AUTOSAR XML (schema 4-3-0)
package /ComponentTypes
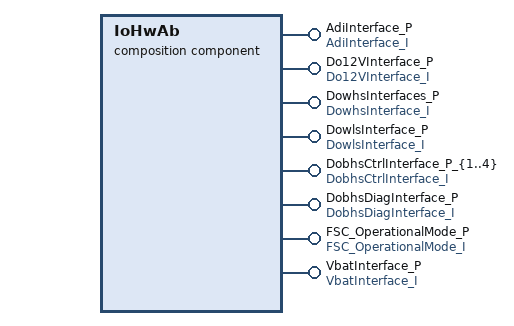
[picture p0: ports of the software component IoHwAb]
  composition sw component type IoHwAb
    11 x provide port:
      AdiInterface_P: provided-interface=AdiInterface_I
      Do12VInterface_P: provided-interface=Do12VInterface_I
      DowhsInterfaces_P: provided-interface=DowhsInterface_I
      DowlsInterface_P: provided-interface=DowlsInterface_I
      DobhsCtrlInterface_P_{1..4}: provided-interface=DobhsCtrlInterface_I
      DobhsDiagInterface_P: server-com-spec{operation=IoHwAbOperation, queue-length=1}, provided-interface=DobhsDiagInterface_I
      FSC_OperationalMode_P: provided-com-specs=[{operation=FSC_OperationalMode, queue-length=1}, {operation=VbatInterface_P, queue-length=1}], provided-interface=FSC_OperationalMode_I
      VbatInterface_P: provided-interface=VbatInterface_I
        provided-com-specs:
          operation=DobhsCtrlInterface_P_4, queue-length=1
          operation=DobhsCtrlInterface_P_5, queue-length=1
          operation=DobhsCtrlInterface_P_3, queue-length=1
          operation=DobhsCtrlInterface_P_2, queue-length=1
          operation=DobhsCtrlInterface_P_1, queue-length=1
          operation=FSC_OperationalMode, queue-length=1
          operation=VbatInterface_P, queue-length=1
    component IoHwAb_ASIL: type=IoHwAb_ASIL
    component IoHwAb_QM: type=IoHwAb_QM
    delegate IoHwAb_ASIL.FSC_OperationalMode <-> outer port FSC_OperationalMode_P
    delegate IoHwAb_ASIL.VbatInterface_P <-> outer port VbatInterface_P
    delegate IoHwAb_QM.AdiInterface_P <-> outer port AdiInterface_P
    delegate IoHwAb_ASIL.DobhsCtrlInterface_P_{1..4} <-> outer port DobhsCtrlInterface_P_{1..4}
    delegate IoHwAb_ASIL.DobhsDiagInterface_P <-> outer port DobhsDiagInterface_P
    delegate IoHwAb_QM.Do12VInterface_P <-> outer port Do12VInterface_P
    delegate IoHwAb_QM.DowhsInterfaces_P <-> outer port DowhsInterfaces_P
    delegate IoHwAb_QM.DowlsInterface_P <-> outer port DowlsInterface_P
    connect IoHwAb_ASIL.FSC_OperationalMode -> IoHwAb_QM.FSC_OperationalMode_P
    connect IoHwAb_ASIL.VbatInterface_P -> IoHwAb_QM.VbatInterface_P
